# TESTCHIP register map
dap-e2e synthetic device
CPU: CM3, little endian
Registers are 32-bit, access not given, no defined reset value unless marked. A register's access mark holds for its fields unless they carry their own. Offsets are from the block's base; lines under a group give offsets from that group; [hi:lo] are bit positions; {n}, {i} and the like mark numbered series; 'fields as' and 'values as' point back to an identical list; <NAME> marks a mode.

## Memory map
0x2000F000 TESTP size 0x10 — Test peripheral backed by RAM

## TESTP — Test peripheral backed by RAM
Base 0x2000F000
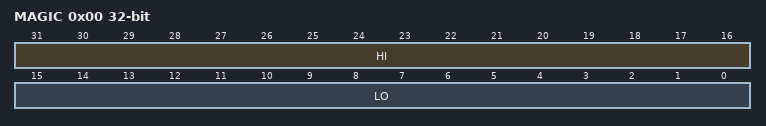
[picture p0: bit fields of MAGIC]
0x00 MAGIC — Written by the firmware at startup
  [31:16] HI — High half
  [15:0] LO — Low half
